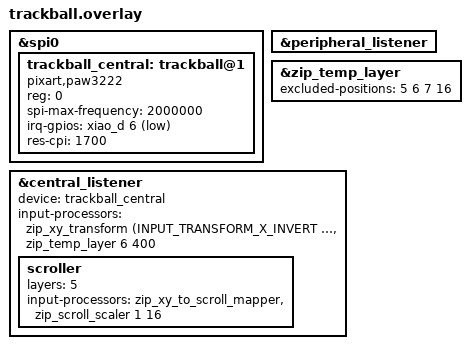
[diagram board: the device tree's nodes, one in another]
&spi0 {
    status = "okay";

    trackball_central: trackball@1 {
        status = "okay";
        compatible = "pixart,paw3222";
        reg = <0>;
        spi-max-frequency = <2000000>;
        irq-gpios = <&xiao_d 6 (GPIO_ACTIVE_LOW | GPIO_PULL_UP)>;
        res-cpi = <1700>;
    };
};

// ペリフェラル（split経由）のリスナーを有効化
&peripheral_listener {
    status = "okay";
};

// excluded-positions以外のキーを押すとAMLが解除される。positionsは、lism.dtsiのpositionsと同じ順番で指定する必要がある。
&zip_temp_layer {
    excluded-positions = <
        5 // y 
        6 // U
        7 // I
        16 // J
    >;
};

// セントラルのリスナーを有効化し、deviceを紐付け
&central_listener {
    status = "okay";
    device = <&trackball_central>;
    input-processors = 
        <&zip_xy_transform (INPUT_TRANSFORM_X_INVERT | INPUT_TRANSFORM_Y_INVERT)>,
        <&zip_temp_layer 6 400>;

    scroller {
        layers = <5>;
        input-processors = 
            <&zip_xy_to_scroll_mapper>,
            <&zip_scroll_scaler 1 16>;
    };
};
